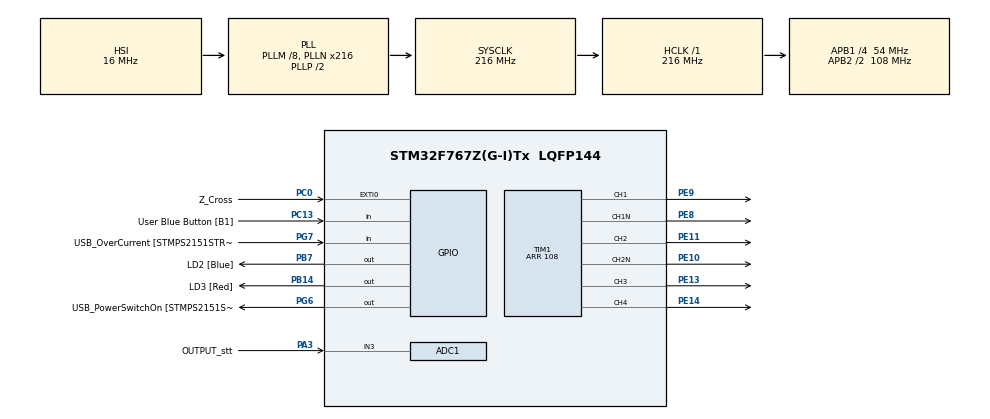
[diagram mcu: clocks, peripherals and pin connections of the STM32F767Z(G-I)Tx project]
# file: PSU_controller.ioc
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ADC1.Channel-0\#ChannelRegularConversion=ADC_CHANNEL_3
ADC1.ClockPrescaler=ADC_CLOCK_SYNC_PCLK_DIV4
ADC1.ContinuousConvMode=DISABLE
ADC1.DMAContinuousRequests=DISABLE
ADC1.DataAlign=ADC_DATAALIGN_RIGHT
ADC1.DiscontinuousConvMode=DISABLE
ADC1.EOCSelection=ADC_EOC_SINGLE_CONV
ADC1.EnableAnalogWatchDog=false
ADC1.ExternalTrigConvEdge=ADC_EXTERNALTRIGCONVEDGE_NONE
ADC1.InjNumberOfConversion=0
ADC1.NbrOfConversion=1
ADC1.NbrOfConversionFlag=1
ADC1.Rank-0\#ChannelRegularConversion=1
ADC1.Resolution=ADC_RESOLUTION_12B
ADC1.SamplingTime-0\#ChannelRegularConversion=ADC_SAMPLETIME_3CYCLES
ADC1.ScanConvMode=DISABLE
ADC1.master=1
CORTEX_M7.FlashInterface=AXI_Enabled
Dma.ADC1.0.Direction=DMA_PERIPH_TO_MEMORY
Dma.ADC1.0.FIFOMode=DMA_FIFOMODE_DISABLE
Dma.ADC1.0.Instance=DMA2_Stream0
Dma.ADC1.0.MemDataAlignment=DMA_MDATAALIGN_HALFWORD
Dma.ADC1.0.MemInc=DMA_MINC_ENABLE
Dma.ADC1.0.Mode=DMA_NORMAL
Dma.ADC1.0.PeriphDataAlignment=DMA_PDATAALIGN_HALFWORD
Dma.ADC1.0.PeriphInc=DMA_PINC_DISABLE
Dma.ADC1.0.Priority=DMA_PRIORITY_LOW
Dma.Request0=ADC1
Mcu.Family=STM32F7
Mcu.Name=STM32F767Z(G-I)Tx
Mcu.Package=LQFP144
NVIC.ADC_IRQn=true\:0\:0\:false\:false\:true
NVIC.DMA2_Stream0_IRQn=true\:0\:0\:false\:false\:true
NVIC.EXTI0_IRQn=true\:0\:0\:false\:false\:true
NVIC.PriorityGroup=NVIC_PRIORITYGROUP_4
NVIC.TIM1_BRK_TIM9_IRQn=true\:0\:0\:false\:false\:true
NVIC.TIM1_UP_TIM10_IRQn=true\:0\:0\:false\:false\:true
PA1.GPIO_Label=RMII_REF_CLK [LAN8742A-CZ-TR_REFCLK0]
PA1.Signal=ETH_REF_CLK
PA10.GPIO_Label=USB_ID
PA10.Signal=USB_OTG_FS_ID
PA11.GPIO_Label=USB_DM
PA11.Signal=USB_OTG_FS_DM
PA12.GPIO_Label=USB_DP
PA12.Signal=USB_OTG_FS_DP
PA13.GPIO_Label=TMS
PA13.Signal=SYS_JTMS-SWDIO
PA14.GPIO_Label=TCK
PA14.Signal=SYS_JTCK-SWCLK
PA2.GPIO_Label=RMII_MDIO [LAN8742A-CZ-TR_MDIO]
PA2.Signal=ETH_MDIO
PA3.GPIO_Label=OUTPUT_stt
PA3.Signal=ADCx_IN3
PA7.GPIO_Label=RMII_CRS_DV [LAN8742A-CZ-TR_CRS_DV]
PA7.Signal=ETH_CRS_DV
PA8.GPIO_Label=USB_SOF [TP1]
PA8.Signal=USB_OTG_FS_SOF
PA9.GPIO_Label=USB_VBUS
PA9.Signal=USB_OTG_FS_VBUS
PB13.GPIO_Label=RMII_TXD1 [LAN8742A-CZ-TR_TXD1]
PB13.Signal=ETH_TXD1
PB14.GPIO_Label=LD3 [Red]
PB14.Signal=GPIO_Output
PB3.GPIO_Label=SW0
PB3.Signal=SYS_JTDO-SWO
PB7.GPIO_Label=LD2 [Blue]
PB7.Signal=GPIO_Output
PC0.GPIO_Label=Z_Cross
PC0.Signal=GPXTI0
PC1.GPIO_Label=RMII_MDC [LAN8742A-CZ-TR_MDC]
PC1.Signal=ETH_MDC
PC13.GPIO_Label=User Blue Button [B1]
PC13.Signal=GPIO_Input
PC14/OSC32_IN.Signal=RCC_OSC32_IN
PC15/OSC32_OUT.Signal=RCC_OSC32_OUT
PC4.GPIO_Label=RMII_RXD0 [LAN8742A-CZ-TR_RXD0]
PC4.Signal=ETH_RXD0
PC5.GPIO_Label=RMII_RXD1 [LAN8742A-CZ-TR_RXD1]
PC5.Signal=ETH_RXD1
PD8.GPIO_Label=STLK_RX [STM32F103CBT6_PA3]
PD8.Signal=USART3_TX
PD9.GPIO_Label=STLK_TX [STM32F103CBT6_PA2]
PD9.Signal=USART3_RX
PE10.GPIO_Speed=GPIO_SPEED_FREQ_VERY_HIGH
PE10.Mode=PWM Generation2 CH2 CH2N
PE10.Signal=TIM1_CH2N
PE11.GPIO_Speed=GPIO_SPEED_FREQ_VERY_HIGH
PE11.Signal=S_TIM1_CH2
PE13.Signal=S_TIM1_CH3
PE14.Signal=S_TIM1_CH4
PE8.GPIO_Speed=GPIO_SPEED_FREQ_VERY_HIGH
PE8.Mode=PWM Generation1 CH1 CH1N
PE8.Signal=TIM1_CH1N
PE9.GPIO_Speed=GPIO_SPEED_FREQ_VERY_HIGH
PE9.Signal=S_TIM1_CH1
PG11.GPIO_Label=RMII_TX_EN [LAN8742A-CZ-TR_TXEN]
PG11.Signal=ETH_TX_EN
PG13.GPIO_Label=RMII_TXD0 [LAN8742A-CZ-TR_TXD0]
PG13.Signal=ETH_TXD0
PG6.GPIO_Label=USB_PowerSwitchOn [STMPS2151STR_EN]
PG6.Signal=GPIO_Output
PG7.GPIO_Label=USB_OverCurrent [STMPS2151STR_FAULT]
PG7.Signal=GPIO_Input
PH0/OSC_IN.GPIO_Label=MCO [STM32F103CBT6_PA8]
PH0/OSC_IN.Signal=RCC_OSC_IN
PH1/OSC_OUT.Signal=RCC_OSC_OUT
ProjectManager.HeapSize=0x200
ProjectManager.StackSize=0x400
ProjectManager.TargetToolchain=MDK-ARM V5
RCC.48MHZClocksFreq_Value=24000000
RCC.AHBFreq_Value=216000000
RCC.APB1CLKDivider=RCC_HCLK_DIV4
RCC.APB1Freq_Value=54000000
RCC.APB1TimFreq_Value=108000000
RCC.APB2CLKDivider=RCC_HCLK_DIV2
RCC.APB2Freq_Value=108000000
RCC.APB2TimFreq_Value=216000000
RCC.CortexFreq_Value=216000000
RCC.HCLKFreq_Value=216000000
RCC.HSE_VALUE=16000000
RCC.HSI_VALUE=16000000
RCC.LSE_VALUE=32768
RCC.PLLM=8
RCC.PLLMUL=RCC_PLL_MUL9
RCC.PLLN=216
RCC.PRESCALERUSB=RCC_USBCLKSOURCE_PLL_DIV1_5
RCC.SYSCLKFreq_VALUE=216000000
RCC.SYSCLKSource=RCC_SYSCLKSOURCE_PLLCLK
RCC.SYSCLKSourceVirtual=RCC_SYSCLKSOURCE_PLLCLK
RCC.USBFreq_Value=216000000
RCC.VCOOutputFreq_Value=432000000
SH.ADCx_IN3.0=ADC1_IN3,IN3
SH.S_TIM1_CH1.0=TIM1_CH1,PWM Generation1 CH1 CH1N
SH.S_TIM1_CH2.0=TIM1_CH2,PWM Generation2 CH2 CH2N
SH.S_TIM1_CH3.0=TIM1_CH3,PWM Generation3 CH3
SH.S_TIM1_CH4.0=TIM1_CH4,PWM Generation4 CH4
TIM1.AutomaticOutput=TIM_AUTOMATICOUTPUT_ENABLE
TIM1.Channel-PWM\ Generation2\ CH2\ CH2N=TIM_CHANNEL_2
TIM1.Channel-PWM\ Generation3\ CH3=TIM_CHANNEL_3
TIM1.Channel-PWM\ Generation4\ CH4=TIM_CHANNEL_4
TIM1.CounterMode=TIM_COUNTERMODE_CENTERALIGNED1
TIM1.DeadTime=10
TIM1.OCFastMode_PWM-PWM\ Generation1\ CH1\ CH1N=TIM_OCFAST_DISABLE
TIM1.OCFastMode_PWM-PWM\ Generation2\ CH2\ CH2N=TIM_OCFAST_DISABLE
TIM1.OCMode_PWM-PWM\ Generation1\ CH1\ CH1N=TIM_OCMODE_ASSYMETRIC_PWM1
TIM1.OCMode_PWM-PWM\ Generation2\ CH2\ CH2N=TIM_OCMODE_ASSYMETRIC_PWM1
TIM1.OCMode_PWM-PWM\ Generation3\ CH3=TIM_OCMODE_ASSYMETRIC_PWM1
TIM1.OCMode_PWM-PWM\ Generation4\ CH4=TIM_OCMODE_ASSYMETRIC_PWM1
TIM1.OCNIdleState_1=TIM_OCNIDLESTATE_RESET
TIM1.OCNIdleState_2=TIM_OCNIDLESTATE_RESET
TIM1.OCNPolarity_1=TIM_OCNPOLARITY_HIGH
TIM1.OCNPolarity_2=TIM_OCNPOLARITY_HIGH
TIM1.OffStateIDLEMode=TIM_OSSI_DISABLE
TIM1.OffStateRunMode=TIM_OSSR_DISABLE
TIM1.Period=108
TIM1.Pulse-PWM\ Generation1\ CH1\ CH1N=27
TIM1.Pulse-PWM\ Generation2\ CH2\ CH2N=81
VP_TIM1_VS_ClockSourceINT.Mode=Internal
board=NUCLEO-F767ZI

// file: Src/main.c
/**
  ******************************************************************************
  * File Name          : main.c
  * Description        : Main program body
  ******************************************************************************
  *
  * COPYRIGHT(c) 2016 STMicroelectronics
  *
  * Redistribution and use in source and binary forms, with or without modification,
  * are permitted provided that the following conditions are met:
  *   1. Redistributions of source code must retain the above copyright notice,
  *      this list of conditions and the following disclaimer.
  *   2. Redistributions in binary form must reproduce the above copyright notice,
  *      this list of conditions and the following disclaimer in the documentation
  *      and/or other materials provided with the distribution.
  *   3. Neither the name of STMicroelectronics nor the names of its contributors
  *      may be used to endorse or promote products derived from this software
  *      without specific prior written permission.
  *
  * THIS SOFTWARE IS PROVIDED BY THE COPYRIGHT HOLDERS AND CONTRIBUTORS "AS IS"
  * AND ANY EXPRESS OR IMPLIED WARRANTIES, INCLUDING, BUT NOT LIMITED TO, THE
  * IMPLIED WARRANTIES OF MERCHANTABILITY AND FITNESS FOR A PARTICULAR PURPOSE ARE
  * DISCLAIMED. IN NO EVENT SHALL THE COPYRIGHT HOLDER OR CONTRIBUTORS BE LIABLE
  * FOR ANY DIRECT, INDIRECT, INCIDENTAL, SPECIAL, EXEMPLARY, OR CONSEQUENTIAL
  * DAMAGES (INCLUDING, BUT NOT LIMITED TO, PROCUREMENT OF SUBSTITUTE GOODS OR
  * SERVICES; LOSS OF USE, DATA, OR PROFITS; OR BUSINESS INTERRUPTION) HOWEVER
  * CAUSED AND ON ANY THEORY OF LIABILITY, WHETHER IN CONTRACT, STRICT LIABILITY,
  * OR TORT (INCLUDING NEGLIGENCE OR OTHERWISE) ARISING IN ANY WAY OUT OF THE USE
  * OF THIS SOFTWARE, EVEN IF ADVISED OF THE POSSIBILITY OF SUCH DAMAGE.
  *
  ******************************************************************************
  */
#include "stm32f7xx_hal.h"
#include "adc.h"
#include "dma.h"
#include "tim.h"
#include "gpio.h"

/* USER CODE BEGIN PV */
/* Private variables ---------------------------------------------------------*/

/* USER CODE END PV */

void SystemClock_Config(void);
void Error_Handler(void);

/* USER CODE BEGIN PFP */
/* Private function prototypes -----------------------------------------------*/

/* USER CODE END PFP */

int main(void)
{

  /* MCU Configuration----------------------------------------------------------*/

  /* Reset of all peripherals, Initializes the Flash interface and the Systick. */
  HAL_Init();

  /* Configure the system clock */
  SystemClock_Config();

  /* Initialize all configured peripherals */
  MX_GPIO_Init();
  MX_DMA_Init();
  MX_ADC1_Init();
  MX_TIM1_Init();

  /* USER CODE BEGIN 2 */

		HAL_TIM_PWM_Init(&htim1);
		TIM_CCxChannelCmd(htim1.Instance, TIM_CHANNEL_1, TIM_CCx_ENABLE + TIM_CCxN_ENABLE);
		TIM_CCxChannelCmd(htim1.Instance, TIM_CHANNEL_2, TIM_CCx_ENABLE + TIM_CCxN_ENABLE);
    /* Enable the main output */
    __HAL_TIM_MOE_ENABLE(&htim1);
		/* Enable the Peripheral */
		__HAL_TIM_ENABLE(&htim1);

  /* USER CODE END 2 */

  /* Infinite loop */
  while (1)
  {

  }

}

/** System Clock Configuration
*/
void SystemClock_Config(void)
{

  RCC_OscInitTypeDef RCC_OscInitStruct;
  RCC_ClkInitTypeDef RCC_ClkInitStruct;

  __HAL_RCC_PWR_CLK_ENABLE();

  __HAL_PWR_VOLTAGESCALING_CONFIG(PWR_REGULATOR_VOLTAGE_SCALE1);

  RCC_OscInitStruct.OscillatorType = RCC_OSCILLATORTYPE_HSI;
  RCC_OscInitStruct.HSIState = RCC_HSI_ON;
  RCC_OscInitStruct.HSICalibrationValue = 16;
  RCC_OscInitStruct.PLL.PLLState = RCC_PLL_ON;
  RCC_OscInitStruct.PLL.PLLSource = RCC_PLLSOURCE_HSI;
  RCC_OscInitStruct.PLL.PLLM = 8;
  RCC_OscInitStruct.PLL.PLLN = 216;
  RCC_OscInitStruct.PLL.PLLP = RCC_PLLP_DIV2;
  RCC_OscInitStruct.PLL.PLLQ = 2;
  if (HAL_RCC_OscConfig(&RCC_OscInitStruct) != HAL_OK)
  {
    Error_Handler();
  }

  if (HAL_PWREx_EnableOverDrive() != HAL_OK)
  {
    Error_Handler();
  }

  RCC_ClkInitStruct.ClockType = RCC_CLOCKTYPE_HCLK|RCC_CLOCKTYPE_SYSCLK
                              |RCC_CLOCKTYPE_PCLK1|RCC_CLOCKTYPE_PCLK2;
  RCC_ClkInitStruct.SYSCLKSource = RCC_SYSCLKSOURCE_PLLCLK;
  RCC_ClkInitStruct.AHBCLKDivider = RCC_SYSCLK_DIV1;
  RCC_ClkInitStruct.APB1CLKDivider = RCC_HCLK_DIV4;
  RCC_ClkInitStruct.APB2CLKDivider = RCC_HCLK_DIV2;
  if (HAL_RCC_ClockConfig(&RCC_ClkInitStruct, FLASH_LATENCY_7) != HAL_OK)
  {
    Error_Handler();
  }

  HAL_SYSTICK_Config(HAL_RCC_GetHCLKFreq()/1000);

  HAL_SYSTICK_CLKSourceConfig(SYSTICK_CLKSOURCE_HCLK);

  /* SysTick_IRQn interrupt configuration */
  HAL_NVIC_SetPriority(SysTick_IRQn, 0, 0);
}

void Error_Handler(void)
{
  while(1)
  {
  }
}

/************************ (C) COPYRIGHT STMicroelectronics *****END OF FILE****/
